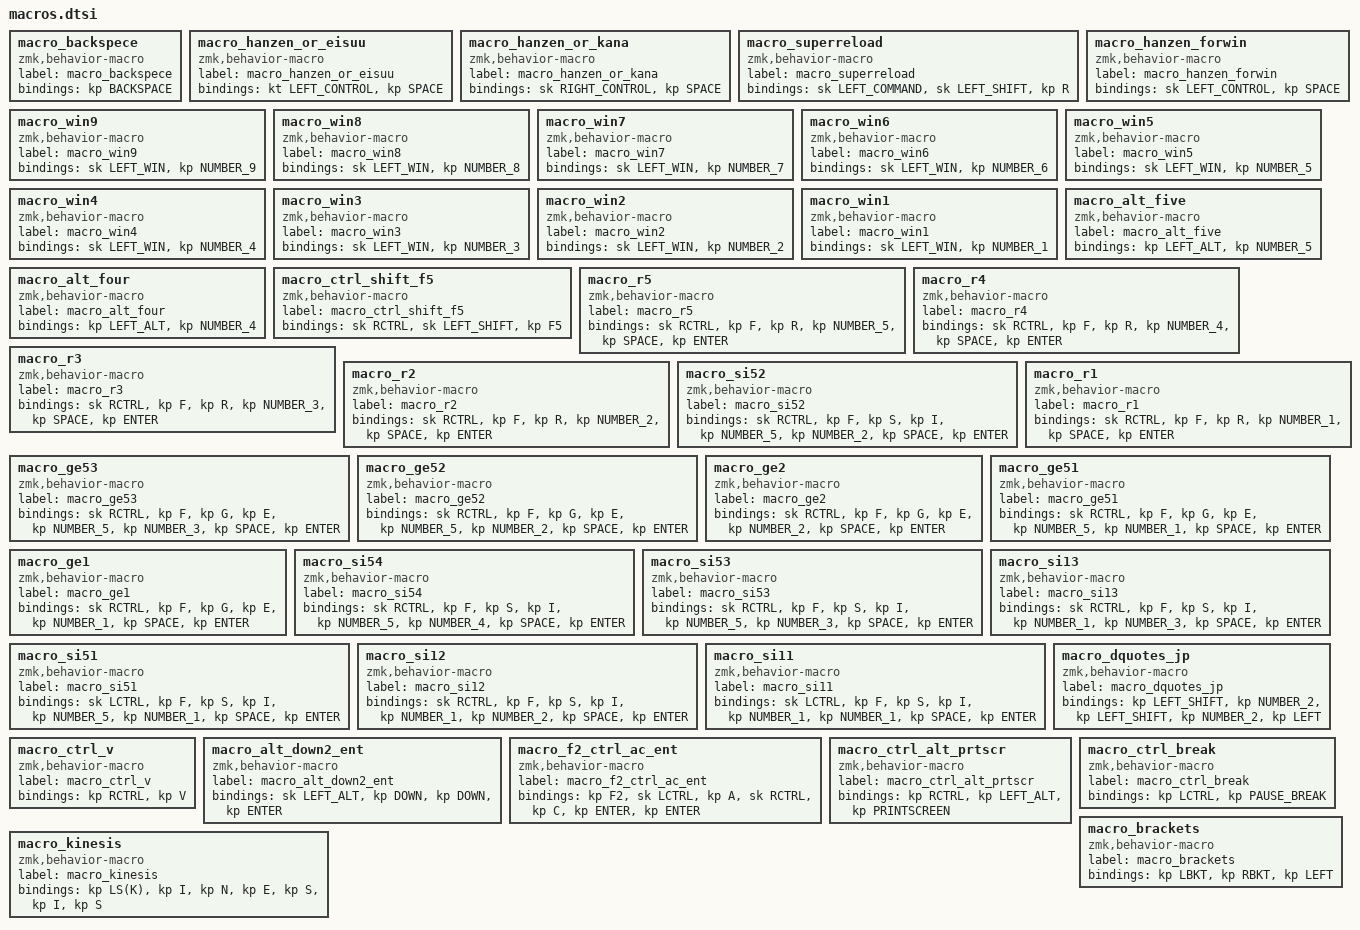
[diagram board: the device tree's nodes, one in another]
macro_backspece: macro_backspece{
compatible = "zmk,behavior-macro";
label = "macro_backspece";
#binding-cells = <0>;
bindings = <&kp BACKSPACE>;
};
macro_hanzen_or_eisuu: macro_hanzen_or_eisuu{
compatible = "zmk,behavior-macro";
label = "macro_hanzen_or_eisuu";
#binding-cells = <0>;
bindings = <&kt LEFT_CONTROL>, <&kp SPACE>;
};
macro_hanzen_or_kana: macro_hanzen_or_kana{
compatible = "zmk,behavior-macro";
label = "macro_hanzen_or_kana";
#binding-cells = <0>;
bindings = <&sk RIGHT_CONTROL>, <&kp SPACE>;
};
macro_superreload: macro_superreload{
compatible = "zmk,behavior-macro";
label = "macro_superreload";
#binding-cells = <0>;
bindings = <&sk LEFT_COMMAND>, <&sk LEFT_SHIFT>, <&kp R>;
};
macro_hanzen_forwin: macro_hanzen_forwin{
compatible = "zmk,behavior-macro";
label = "macro_hanzen_forwin";
#binding-cells = <0>;
bindings = <&sk LEFT_CONTROL>, <&kp SPACE>;
};
macro_win9: macro_win9{
compatible = "zmk,behavior-macro";
label = "macro_win9";
#binding-cells = <0>;
bindings = <&sk LEFT_WIN>, <&kp NUMBER_9>;
};
macro_win8: macro_win8{
compatible = "zmk,behavior-macro";
label = "macro_win8";
#binding-cells = <0>;
bindings = <&sk LEFT_WIN>, <&kp NUMBER_8>;
};
macro_win7: macro_win7{
compatible = "zmk,behavior-macro";
label = "macro_win7";
#binding-cells = <0>;
bindings = <&sk LEFT_WIN>, <&kp NUMBER_7>;
};
macro_win6: macro_win6{
compatible = "zmk,behavior-macro";
label = "macro_win6";
#binding-cells = <0>;
bindings = <&sk LEFT_WIN>, <&kp NUMBER_6>;
};
macro_win5: macro_win5{
compatible = "zmk,behavior-macro";
label = "macro_win5";
#binding-cells = <0>;
bindings = <&sk LEFT_WIN>, <&kp NUMBER_5>;
};
macro_win4: macro_win4{
compatible = "zmk,behavior-macro";
label = "macro_win4";
#binding-cells = <0>;
bindings = <&sk LEFT_WIN>, <&kp NUMBER_4>;
};
macro_win3: macro_win3{
compatible = "zmk,behavior-macro";
label = "macro_win3";
#binding-cells = <0>;
bindings = <&sk LEFT_WIN>, <&kp NUMBER_3>;
};
macro_win2: macro_win2{
compatible = "zmk,behavior-macro";
label = "macro_win2";
#binding-cells = <0>;
bindings = <&sk LEFT_WIN>, <&kp NUMBER_2>;
};
macro_win1: macro_win1{
compatible = "zmk,behavior-macro";
label = "macro_win1";
#binding-cells = <0>;
bindings = <&sk LEFT_WIN>, <&kp NUMBER_1>;
};
macro_alt_five: macro_alt_five{
compatible = "zmk,behavior-macro";
label = "macro_alt_five";
#binding-cells = <0>;
bindings = <&kp LEFT_ALT>, <&kp NUMBER_5>;
};
macro_alt_four: macro_alt_four{
compatible = "zmk,behavior-macro";
label = "macro_alt_four";
#binding-cells = <0>;
bindings = <&kp LEFT_ALT>, <&kp NUMBER_4>;
};
macro_ctrl_shift_f5: macro_ctrl_shift_f5{
compatible = "zmk,behavior-macro";
label = "macro_ctrl_shift_f5";
#binding-cells = <0>;
bindings = <&sk RCTRL>, <&sk LEFT_SHIFT>, <&kp F5>;
};
macro_r5: macro_r5{
compatible = "zmk,behavior-macro";
label = "macro_r5";
#binding-cells = <0>;
bindings = <&sk RCTRL>, <&kp F>, <&kp R>, <&kp NUMBER_5>, <&kp SPACE>, <&kp ENTER>;
};
macro_r4: macro_r4{
compatible = "zmk,behavior-macro";
label = "macro_r4";
#binding-cells = <0>;
bindings = <&sk RCTRL>, <&kp F>, <&kp R>, <&kp NUMBER_4>, <&kp SPACE>, <&kp ENTER>;
};
macro_r3: macro_r3{
compatible = "zmk,behavior-macro";
label = "macro_r3";
#binding-cells = <0>;
bindings = <&sk RCTRL>, <&kp F>, <&kp R>, <&kp NUMBER_3>, <&kp SPACE>, <&kp ENTER>;
};
macro_r2: macro_r2{
compatible = "zmk,behavior-macro";
label = "macro_r2";
#binding-cells = <0>;
bindings = <&sk RCTRL>, <&kp F>, <&kp R>, <&kp NUMBER_2>, <&kp SPACE>, <&kp ENTER>;
};
macro_si52: macro_si52{
compatible = "zmk,behavior-macro";
label = "macro_si52";
#binding-cells = <0>;
bindings = <&sk RCTRL>, <&kp F>, <&kp S>, <&kp I>, <&kp NUMBER_5>, <&kp NUMBER_2>, <&kp SPACE>, <&kp ENTER>;
};
macro_r1: macro_r1{
compatible = "zmk,behavior-macro";
label = "macro_r1";
#binding-cells = <0>;
bindings = <&sk RCTRL>, <&kp F>, <&kp R>, <&kp NUMBER_1>, <&kp SPACE>, <&kp ENTER>;
};
macro_ge53: macro_ge53{
compatible = "zmk,behavior-macro";
label = "macro_ge53";
#binding-cells = <0>;
bindings = <&sk RCTRL>, <&kp F>, <&kp G>, <&kp E>, <&kp NUMBER_5>, <&kp NUMBER_3>, <&kp SPACE>, <&kp ENTER>;
};
macro_ge52: macro_ge52{
compatible = "zmk,behavior-macro";
label = "macro_ge52";
#binding-cells = <0>;
bindings = <&sk RCTRL>, <&kp F>, <&kp G>, <&kp E>, <&kp NUMBER_5>, <&kp NUMBER_2>, <&kp SPACE>, <&kp ENTER>;
};
macro_ge2: macro_ge2{
compatible = "zmk,behavior-macro";
label = "macro_ge2";
#binding-cells = <0>;
bindings = <&sk RCTRL>, <&kp F>, <&kp G>, <&kp E>, <&kp NUMBER_2>, <&kp SPACE>, <&kp ENTER>;
};
macro_ge51: macro_ge51{
compatible = "zmk,behavior-macro";
label = "macro_ge51";
#binding-cells = <0>;
bindings = <&sk RCTRL>, <&kp F>, <&kp G>, <&kp E>, <&kp NUMBER_5>, <&kp NUMBER_1>, <&kp SPACE>, <&kp ENTER>;
};
macro_ge1: macro_ge1{
compatible = "zmk,behavior-macro";
label = "macro_ge1";
#binding-cells = <0>;
bindings = <&sk RCTRL>, <&kp F>, <&kp G>, <&kp E>, <&kp NUMBER_1>, <&kp SPACE>, <&kp ENTER>;
};
macro_si54: macro_si54{
compatible = "zmk,behavior-macro";
label = "macro_si54";
#binding-cells = <0>;
bindings = <&sk RCTRL>, <&kp F>, <&kp S>, <&kp I>, <&kp NUMBER_5>, <&kp NUMBER_4>, <&kp SPACE>, <&kp ENTER>;
};
macro_si53: macro_si53{
compatible = "zmk,behavior-macro";
label = "macro_si53";
#binding-cells = <0>;
bindings = <&sk RCTRL>, <&kp F>, <&kp S>, <&kp I>, <&kp NUMBER_5>, <&kp NUMBER_3>, <&kp SPACE>, <&kp ENTER>;
};
macro_si13: macro_si13{
compatible = "zmk,behavior-macro";
label = "macro_si13";
#binding-cells = <0>;
bindings = <&sk RCTRL>, <&kp F>, <&kp S>, <&kp I>, <&kp NUMBER_1>, <&kp NUMBER_3>, <&kp SPACE>, <&kp ENTER>;
};
macro_si51: macro_si51{
compatible = "zmk,behavior-macro";
label = "macro_si51";
#binding-cells = <0>;
bindings = <&sk LCTRL>, <&kp F>, <&kp S>, <&kp I>, <&kp NUMBER_5>, <&kp NUMBER_1>, <&kp SPACE>, <&kp ENTER>;
};
macro_si12: macro_si12{
compatible = "zmk,behavior-macro";
label = "macro_si12";
#binding-cells = <0>;
bindings = <&sk RCTRL>, <&kp F>, <&kp S>, <&kp I>, <&kp NUMBER_1>, <&kp NUMBER_2>, <&kp SPACE>, <&kp ENTER>;
};
macro_si11: macro_si11{
compatible = "zmk,behavior-macro";
label = "macro_si11";
#binding-cells = <0>;
bindings = <&sk LCTRL>, <&kp F>, <&kp S>, <&kp I>, <&kp NUMBER_1>, <&kp NUMBER_1>, <&kp SPACE>, <&kp ENTER>;
};
macro_dquotes_jp: macro_dquotes_jp{
compatible = "zmk,behavior-macro";
label = "macro_dquotes_jp";
#binding-cells = <0>;
bindings = <&kp LEFT_SHIFT>, <&kp NUMBER_2>, <&kp LEFT_SHIFT>, <&kp NUMBER_2>, <&kp LEFT>;
};
macro_ctrl_v: macro_ctrl_v{
compatible = "zmk,behavior-macro";
label = "macro_ctrl_v";
#binding-cells = <0>;
bindings = <&kp RCTRL>, <&kp V>;
};
macro_alt_down2_ent: macro_alt_down2_ent{
compatible = "zmk,behavior-macro";
label = "macro_alt_down2_ent";
#binding-cells = <0>;
bindings = <&sk LEFT_ALT>, <&kp DOWN>, <&kp DOWN>, <&kp ENTER>;
};
macro_f2_ctrl_ac_ent: macro_f2_ctrl_ac_ent{
compatible = "zmk,behavior-macro";
label = "macro_f2_ctrl_ac_ent";
#binding-cells = <0>;
bindings = <&kp F2>, <&sk LCTRL>, <&kp A>, <&sk RCTRL>, <&kp C>, <&kp ENTER>, <&kp ENTER>;
};
macro_ctrl_alt_prtscr: macro_ctrl_alt_prtscr{
compatible = "zmk,behavior-macro";
label = "macro_ctrl_alt_prtscr";
#binding-cells = <0>;
bindings = <&kp RCTRL>, <&kp LEFT_ALT>, <&kp PRINTSCREEN>;
};
macro_ctrl_break: macro_ctrl_break{
compatible = "zmk,behavior-macro";
label = "macro_ctrl_break";
#binding-cells = <0>;
bindings = <&kp LCTRL>, <&kp PAUSE_BREAK>;
};
macro_brackets: macro_brackets{
compatible = "zmk,behavior-macro";
label = "macro_brackets";
#binding-cells = <0>;
bindings = <&kp LBKT>, <&kp RBKT>, <&kp LEFT>;
};
macro_kinesis: macro_kinesis{
compatible = "zmk,behavior-macro";
label = "macro_kinesis";
#binding-cells = <0>;
bindings = <&kp LS(K)>, <&kp I>, <&kp N>, <&kp E>, <&kp S>, <&kp I>, <&kp S>;
};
